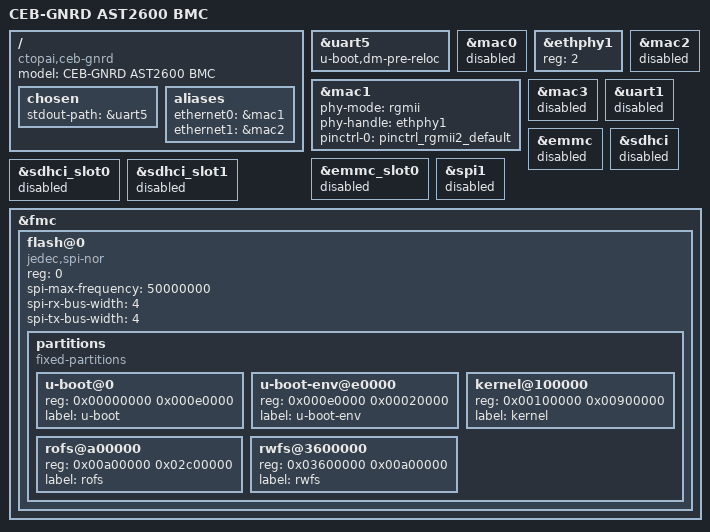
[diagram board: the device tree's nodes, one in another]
// SPDX-License-Identifier: GPL-2.0-or-later
/dts-v1/;

#include "ast2600-evb.dts"

/ {
	model = "CEB-GNRD AST2600 BMC";
	compatible = "ctopai,ceb-gnrd", "aspeed,ast2600";

	chosen {
		stdout-path = &uart5;
	};

	aliases {
		ethernet0 = &mac1;
		ethernet1 = &mac2;
	};
};

/* Keep UART5 available from SPL through U-Boot for board bring-up logs. */
&uart5 {
	u-boot,dm-pre-reloc;
	status = "okay";
};

/* Physical MAC1 and MAC4 are not routed on this board. */
&mac0 {
	status = "disabled";
};

/* RTL8211FS-CG straps (schematic): PHYAD = 002 (MDIO address 2, per the schematic note), no RGMII delay. */
&ethphy1 {
	reg = <2>;
};

/* Physical MAC2: independent RJ45 through the RTL8211FS-CG PHY. */
&mac1 {
	status = "okay";
	phy-mode = "rgmii";
	phy-handle = <&ethphy1>;
	pinctrl-names = "default";
	pinctrl-0 = <&pinctrl_rgmii2_default>;
};

/* Physical MAC3: NC-SI to the Intel E810.  U-Boot does not use this port (TFTP
 * boot goes through the RGMII port above), so it is not started here; Linux
 * brings the NC-SI link up with its own device tree and gets its address by
 * DHCP.
 *
 * Do not enable it with a phy-mode: the ftgmac100 NC-SI probe crashed U-Boot
 * (data abort, endless reset loop).  Without a phy-mode the probe only prints
 * "Invalid PHY interface '<NULL>'", so it is simply disabled. */
&mac2 {
	status = "disabled";
};

&mac3 { status = "disabled"; };

/* GPIOM1/NDCD1 is reserved for the Linux BIOS-flash ownership GPIO. */
&uart1 { status = "disabled"; };

/* This board has no eMMC and no SD card: the EVB device tree enables them, which
 * makes U-Boot probe (and print messages about) MMC devices that do not exist. */
&emmc { status = "disabled"; };
&emmc_slot0 { status = "disabled"; };
&sdhci { status = "disabled"; };
&sdhci_slot0 { status = "disabled"; };
&sdhci_slot1 { status = "disabled"; };

/* BIOS SPI1 is updated only from OpenBMC Linux, in single-bit mode. */
&spi1 { status = "disabled"; };

/* The BMC boot device is the 64 MiB W25Q512JV on Firmware SPI (FMC). */
&fmc {
	status = "okay";
	/delete-node/ flash@0;

	flash@0 {
		compatible = "jedec,spi-nor";
		reg = <0>;
		spi-max-frequency = <50000000>;
		spi-rx-bus-width = <4>;
		spi-tx-bus-width = <4>;

		partitions {
			compatible = "fixed-partitions";
			#address-cells = <1>;
			#size-cells = <1>;

			u-boot@0 { reg = <0x00000000 0x000e0000>; label = "u-boot"; };
			u-boot-env@e0000 { reg = <0x000e0000 0x00020000>; label = "u-boot-env"; };
			kernel@100000 { reg = <0x00100000 0x00900000>; label = "kernel"; };
			rofs@a00000 { reg = <0x00a00000 0x02c00000>; label = "rofs"; };
			rwfs@3600000 { reg = <0x03600000 0x00a00000>; label = "rwfs"; };
		};
	};
};
